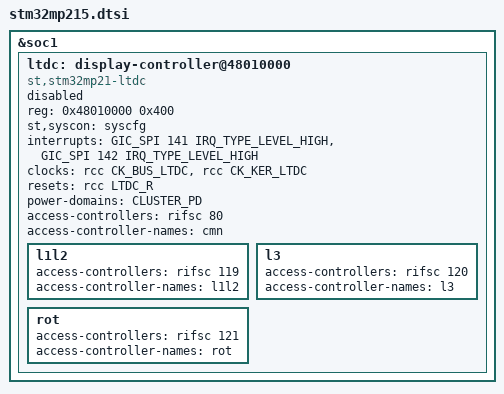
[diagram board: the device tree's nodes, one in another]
// SPDX-License-Identifier: (GPL-2.0-only OR BSD-3-Clause)
/*
 * Copyright (C) STMicroelectronics 2024 - All Rights Reserved
 * Author: Alexandre Torgue <alexandre.torgue@foss.st.com> for STMicroelectronics.
 */
#include "stm32mp213.dtsi"

&soc1 {
	ltdc: display-controller@48010000 {
		compatible = "st,stm32mp21-ltdc";
		reg = <0x48010000 0x400>;
		st,syscon = <&syscfg>;
		interrupts = <GIC_SPI 141 IRQ_TYPE_LEVEL_HIGH>,
			     <GIC_SPI 142 IRQ_TYPE_LEVEL_HIGH>;
		clocks = <&rcc CK_BUS_LTDC>, <&rcc CK_KER_LTDC>;
		clock-names = "bus", "lcd";
		resets = <&rcc LTDC_R>;
		power-domains = <&CLUSTER_PD>;
		status = "disabled";
		access-controllers = <&rifsc 80>;
		access-controller-names = "cmn";

		l1l2 {
			access-controllers = <&rifsc 119>;
			access-controller-names = "l1l2";
		};
		l3 {
			access-controllers = <&rifsc 120>;
			access-controller-names = "l3";
		};
		rot {
			access-controllers = <&rifsc 121>;
			access-controller-names = "rot";
		};
	};
};
